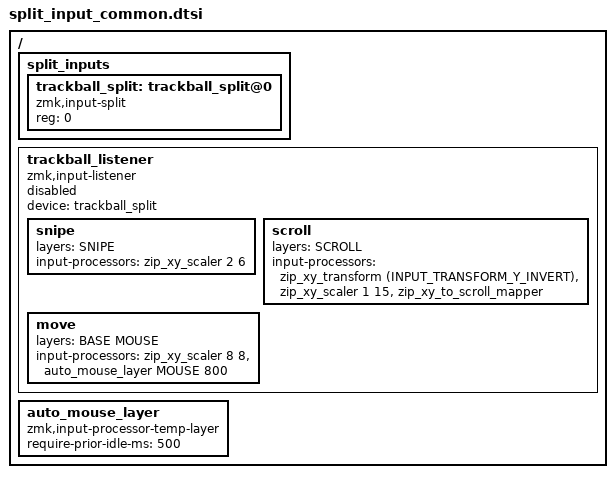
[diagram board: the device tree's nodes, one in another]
#include <dt-bindings/zmk/input_transform.h>
#include <input/processors.dtsi>

#define BASE 0
#define NUM 1
#define NAV 2
#define MOUSE 3
#define SCROLL 4
#define SNIPE 5

/ {
  split_inputs {
    #address-cells = <1>;
    #size-cells = <0>;

    trackball_split: trackball_split@0 {
      compatible = "zmk,input-split";
      reg = <0>;
    };
  };

  trackball_listener: trackball_listener {
    compatible = "zmk,input-listener";
    status = "disabled";
    device = <&trackball_split>;

    snipe {
      layers = <SNIPE>;
      input-processors = <&zip_xy_scaler 2 6>;
    };

    scroll {
      layers = <SCROLL>;
      input-processors = <&zip_xy_transform (INPUT_TRANSFORM_Y_INVERT)>, <&zip_xy_scaler 1 15>, <&zip_xy_to_scroll_mapper>;
    };

    move {
      layers = <BASE MOUSE>;
      input-processors = <&zip_xy_scaler 8 8>, <&auto_mouse_layer MOUSE 800>;
    };
  };

  auto_mouse_layer: auto_mouse_layer {
    compatible = "zmk,input-processor-temp-layer";
    #input-processor-cells = <2>;
    require-prior-idle-ms = <500>;
  };
};
